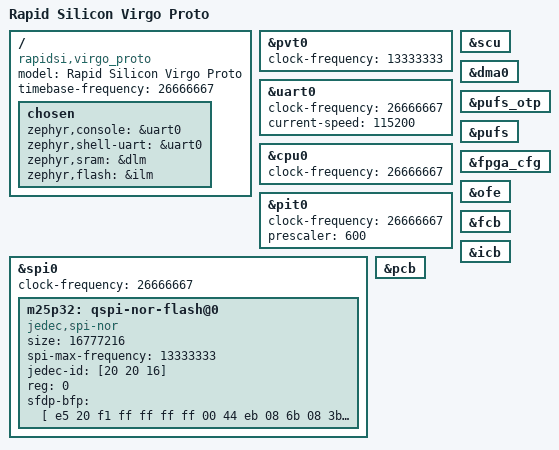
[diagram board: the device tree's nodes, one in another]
/*
 * Copyright (c) 2024 Rapid Silicon
 *
 * SPDX-License-Identifier: Apache-2.0
 */

 /dts-v1/;

 #include <rapidsilicon/rapidsi_virgo.dtsi>

 /
 {
	 model = "Rapid Silicon Virgo Proto";
	 compatible = "rapidsi,virgo_proto";
	 timebase-frequency = <26666667>;
 
	 chosen {
		 zephyr,console = &uart0;
		 zephyr,shell-uart = &uart0;
		 zephyr,sram = &dlm;
		 zephyr,flash = &ilm;
	 };
 };
 
 &pvt0 {
	clock-frequency = <13333333>;
	status = "okay";
 };

 &scu {
	status = "okay";
 };

 &uart0 {
	 clock-frequency = <26666667>;
	 current-speed = <115200>;
	 status = "okay";
 };
 
 &cpu0 {
	clock-frequency = <26666667>;
 };

 &pit0 {
	clock-frequency = <26666667>;
	prescaler = <600>;
	status = "okay";
 };
 
 &dma0 {
	status = "okay";
 };

 &pufs_otp {
	status = "okay";
 };
 
 &pufs {
	status = "okay";
 };
 
 &spi0 {
	status = "okay";
	clock-frequency = <26666667>;
	m25p32: qspi-nor-flash@0 {
		compatible = "jedec,spi-nor";
		size = <16777216>;
		spi-max-frequency = <13333333>;
		jedec-id = [20 20 16]; // ID of flash on soc protoype
		status = "okay";
		reg = <0>;
		sfdp-bfp = [
			e5 20 f1 ff  ff ff ff 00  44 eb 08 6b  08 3b 04 bb
			fe ff ff ff  ff ff 00 ff  ff ff 44 eb  0c D8 0f 52
			10 d8 00 ff
		];
	};
 };
 
 &fpga_cfg {
	status = "okay";
 };

 &ofe {
	status = "okay";
 };

 &fcb {
	status = "okay";
 };

 &icb {
	status = "okay";
 };

 &pcb {
	status = "okay";
 };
